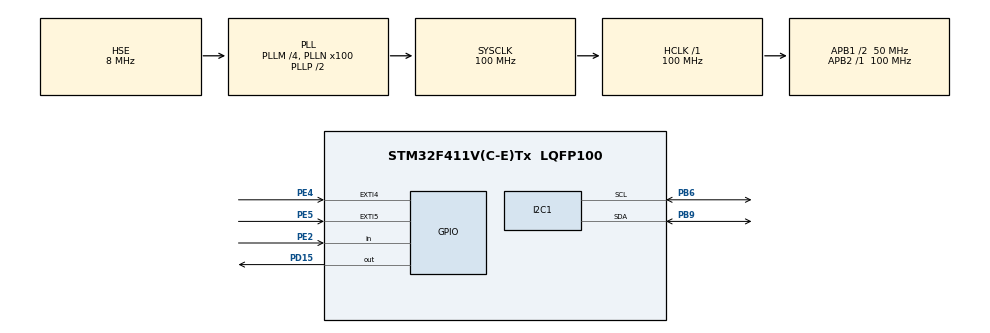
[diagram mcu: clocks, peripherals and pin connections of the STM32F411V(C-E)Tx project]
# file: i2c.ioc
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FREERTOS.Tasks01=defaultTask,24,4096,StartDefaultTask,Default,NULL,Dynamic,NULL,NULL
FREERTOS.configTOTAL_HEAP_SIZE=32768
Mcu.Family=STM32F4
Mcu.Name=STM32F411V(C-E)Tx
Mcu.Package=LQFP100
NVIC.PriorityGroup=NVIC_PRIORITYGROUP_4
NVIC.TIM1_UP_TIM10_IRQn=true\:0\:0\:false\:false\:true\:false\:false\:true
NVIC.TimeBase=TIM1_UP_TIM10_IRQn
NVIC.TimeBaseIP=TIM1
PA13.Mode=Serial_Wire
PA13.Signal=SYS_JTMS-SWDIO
PA14.Mode=Serial_Wire
PA14.Signal=SYS_JTCK-SWCLK
PB6.Mode=I2C
PB6.Signal=I2C1_SCL
PB9.Mode=I2C
PB9.Signal=I2C1_SDA
PD15.Signal=GPIO_Output
PE2.Signal=GPIO_Input
PE4.Signal=GPXTI4
PE5.Signal=GPXTI5
PH0\ -\ OSC_IN.Mode=HSE-External-Oscillator
PH0\ -\ OSC_IN.Signal=RCC_OSC_IN
PH1\ -\ OSC_OUT.Mode=HSE-External-Oscillator
PH1\ -\ OSC_OUT.Signal=RCC_OSC_OUT
ProjectManager.HeapSize=0x200
ProjectManager.StackSize=0x400
ProjectManager.TargetToolchain=STM32CubeIDE
RCC.48MHZClocksFreq_Value=50000000
RCC.AHBFreq_Value=100000000
RCC.APB1CLKDivider=RCC_HCLK_DIV2
RCC.APB1Freq_Value=50000000
RCC.APB1TimFreq_Value=100000000
RCC.APB2Freq_Value=100000000
RCC.APB2TimFreq_Value=100000000
RCC.CortexFreq_Value=100000000
RCC.HCLKFreq_Value=100000000
RCC.HSE_VALUE=8000000
RCC.HSI_VALUE=16000000
RCC.PLLM=4
RCC.PLLN=100
RCC.PLLSourceVirtual=RCC_PLLSOURCE_HSE
RCC.SYSCLKFreq_VALUE=100000000
RCC.SYSCLKSource=RCC_SYSCLKSOURCE_PLLCLK
RCC.VCOOutputFreq_Value=200000000
VP_FREERTOS_VS_CMSIS_V2.Mode=CMSIS_V2
VP_SYS_VS_tim1.Mode=TIM1
board=custom

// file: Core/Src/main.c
/* USER CODE BEGIN Header */
/**
  ******************************************************************************
  * @file           : main.c
  * @brief          : Main program body
  ******************************************************************************
  * @attention
  *
  * <h2><center>&copy; Copyright (c) 2019 STMicroelectronics.
  * All rights reserved.</center></h2>
  *
  * This software component is licensed by ST under BSD 3-Clause license,
  * the "License"; You may not use this file except in compliance with the
  * License. You may obtain a copy of the License at:
  *                        opensource.org/licenses/BSD-3-Clause
  *
  ******************************************************************************
  */
/* USER CODE END Header */

#include "main.h"
#include "cmsis_os.h"

I2C_HandleTypeDef hi2c1;

osThreadId_t defaultTaskHandle;

void SystemClock_Config(void);
static void MX_GPIO_Init(void);
static void MX_I2C1_Init(void);
void StartDefaultTask(void *argument);

int main(void)
{

  /* MCU Configuration--------------------------------------------------------*/

  /* Reset of all peripherals, Initializes the Flash interface and the Systick. */
  HAL_Init();

  /* Configure the system clock */
  SystemClock_Config();

  /* Initialize all configured peripherals */
  MX_GPIO_Init();
  MX_I2C1_Init();
  /* USER CODE BEGIN 2 */
  uint8_t value = 0;
  HAL_StatusTypeDef status = HAL_I2C_Mem_Read(&hi2c1, 0x32, 0x0F, 1, &value, 1, 10000);
  /* USER CODE END 2 */

  osKernelInitialize();

  /* Create the thread(s) */
  /* definition and creation of defaultTask */
  const osThreadAttr_t defaultTask_attributes = {
    .name = "defaultTask",
    .priority = (osPriority_t) osPriorityNormal,
    .stack_size = 4096
  };
  defaultTaskHandle = osThreadNew(StartDefaultTask, NULL, &defaultTask_attributes);

  /* Start scheduler */
  osKernelStart();

  /* We should never get here as control is now taken by the scheduler */

  /* Infinite loop */
  while (1)
  {

  }
}

void SystemClock_Config(void)
{
  RCC_OscInitTypeDef RCC_OscInitStruct = {0};
  RCC_ClkInitTypeDef RCC_ClkInitStruct = {0};

  /** Configure the main internal regulator output voltage
  */
  __HAL_RCC_PWR_CLK_ENABLE();
  __HAL_PWR_VOLTAGESCALING_CONFIG(PWR_REGULATOR_VOLTAGE_SCALE1);
  /** Initializes the CPU, AHB and APB busses clocks
  */
  RCC_OscInitStruct.OscillatorType = RCC_OSCILLATORTYPE_HSE;
  RCC_OscInitStruct.HSEState = RCC_HSE_ON;
  RCC_OscInitStruct.PLL.PLLState = RCC_PLL_ON;
  RCC_OscInitStruct.PLL.PLLSource = RCC_PLLSOURCE_HSE;
  RCC_OscInitStruct.PLL.PLLM = 4;
  RCC_OscInitStruct.PLL.PLLN = 100;
  RCC_OscInitStruct.PLL.PLLP = RCC_PLLP_DIV2;
  RCC_OscInitStruct.PLL.PLLQ = 4;
  if (HAL_RCC_OscConfig(&RCC_OscInitStruct) != HAL_OK)
  {
    Error_Handler();
  }
  /** Initializes the CPU, AHB and APB busses clocks
  */
  RCC_ClkInitStruct.ClockType = RCC_CLOCKTYPE_HCLK|RCC_CLOCKTYPE_SYSCLK
                              |RCC_CLOCKTYPE_PCLK1|RCC_CLOCKTYPE_PCLK2;
  RCC_ClkInitStruct.SYSCLKSource = RCC_SYSCLKSOURCE_PLLCLK;
  RCC_ClkInitStruct.AHBCLKDivider = RCC_SYSCLK_DIV1;
  RCC_ClkInitStruct.APB1CLKDivider = RCC_HCLK_DIV2;
  RCC_ClkInitStruct.APB2CLKDivider = RCC_HCLK_DIV1;

  if (HAL_RCC_ClockConfig(&RCC_ClkInitStruct, FLASH_LATENCY_3) != HAL_OK)
  {
    Error_Handler();
  }
}

static void MX_I2C1_Init(void)
{

  hi2c1.Instance = I2C1;
  hi2c1.Init.ClockSpeed = 100000;
  hi2c1.Init.DutyCycle = I2C_DUTYCYCLE_2;
  hi2c1.Init.OwnAddress1 = 0;
  hi2c1.Init.AddressingMode = I2C_ADDRESSINGMODE_7BIT;
  hi2c1.Init.DualAddressMode = I2C_DUALADDRESS_DISABLE;
  hi2c1.Init.OwnAddress2 = 0;
  hi2c1.Init.GeneralCallMode = I2C_GENERALCALL_DISABLE;
  hi2c1.Init.NoStretchMode = I2C_NOSTRETCH_DISABLE;
  if (HAL_I2C_Init(&hi2c1) != HAL_OK)
  {
    Error_Handler();
  }

}

static void MX_GPIO_Init(void)
{
  GPIO_InitTypeDef GPIO_InitStruct = {0};

  /* GPIO Ports Clock Enable */
  __HAL_RCC_GPIOE_CLK_ENABLE();
  __HAL_RCC_GPIOH_CLK_ENABLE();
  __HAL_RCC_GPIOD_CLK_ENABLE();
  __HAL_RCC_GPIOA_CLK_ENABLE();
  __HAL_RCC_GPIOB_CLK_ENABLE();

  /*Configure GPIO pin Output Level */
  HAL_GPIO_WritePin(GPIOD, GPIO_PIN_15, GPIO_PIN_RESET);

  /*Configure GPIO pin : PE2 */
  GPIO_InitStruct.Pin = GPIO_PIN_2;
  GPIO_InitStruct.Mode = GPIO_MODE_INPUT;
  GPIO_InitStruct.Pull = GPIO_NOPULL;
  HAL_GPIO_Init(GPIOE, &GPIO_InitStruct);

  /*Configure GPIO pins : PE4 PE5 */
  GPIO_InitStruct.Pin = GPIO_PIN_4|GPIO_PIN_5;
  GPIO_InitStruct.Mode = GPIO_MODE_IT_RISING;
  GPIO_InitStruct.Pull = GPIO_NOPULL;
  HAL_GPIO_Init(GPIOE, &GPIO_InitStruct);

  /*Configure GPIO pin : PD15 */
  GPIO_InitStruct.Pin = GPIO_PIN_15;
  GPIO_InitStruct.Mode = GPIO_MODE_OUTPUT_PP;
  GPIO_InitStruct.Pull = GPIO_NOPULL;
  GPIO_InitStruct.Speed = GPIO_SPEED_FREQ_LOW;
  HAL_GPIO_Init(GPIOD, &GPIO_InitStruct);

}

void StartDefaultTask(void *argument)
{
  /* USER CODE BEGIN 5 */
  /* Infinite loop */
  for(;;)
  {
	  HAL_GPIO_TogglePin(GPIOD, GPIO_PIN_15);
	  osDelay(200);
  }
  /* USER CODE END 5 */
}

void HAL_TIM_PeriodElapsedCallback(TIM_HandleTypeDef *htim)
{
  if (htim->Instance == TIM1) {
    HAL_IncTick();
  }
}

void Error_Handler(void)
{
}

/************************ (C) COPYRIGHT STMicroelectronics *****END OF FILE****/
